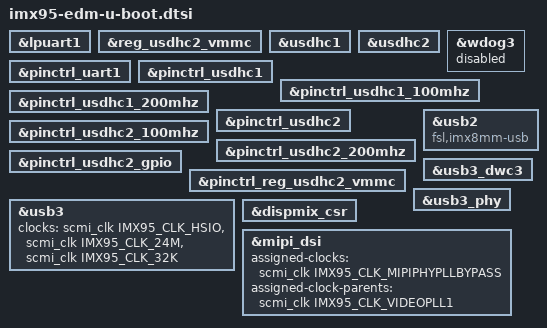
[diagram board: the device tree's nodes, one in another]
// SPDX-License-Identifier: (GPL-2.0+ OR MIT)
/*
 * Copyright 2025 Technexion Ltd.
 *
 * Author: Richard Hu <richard.hu@technexion.com>
 *
 */

#include "imx95-u-boot.dtsi"

&lpuart1 {
	bootph-pre-ram;
};

&reg_usdhc2_vmmc {
	bootph-pre-ram;
};

&usdhc1 {
	bootph-pre-ram;
};

&usdhc2 {
	bootph-pre-ram;
};

&wdog3 {
	status = "disabled";
};

&pinctrl_uart1 {
	bootph-pre-ram;
};

&pinctrl_usdhc1 {
	bootph-pre-ram;
};

&pinctrl_usdhc1_100mhz {
	bootph-pre-ram;
};

&pinctrl_usdhc1_200mhz {
	bootph-pre-ram;
};

&pinctrl_usdhc2 {
	bootph-pre-ram;
};

&pinctrl_usdhc2_100mhz {
	bootph-pre-ram;
};

&pinctrl_usdhc2_200mhz {
	bootph-pre-ram;
};

&pinctrl_usdhc2_gpio {
	bootph-pre-ram;
};

&pinctrl_reg_usdhc2_vmmc {
	bootph-pre-ram;
};

&usb2 {
	compatible = "fsl,imx8mm-usb", "fsl,imx7d-usb";
	/delete-property/power-domains;
};

&usb3 {
	clocks = <&scmi_clk IMX95_CLK_HSIO>,
		 <&scmi_clk IMX95_CLK_24M>,
		 <&scmi_clk IMX95_CLK_32K>;
	clock-names = "hsio", "ref", "suspend";
	/delete-property/power-domains;
	bootph-pre-ram;
};

&usb3_dwc3 {
	bootph-pre-ram;
};

&usb3_phy {
	bootph-pre-ram;
};

&dispmix_csr {
	/delete-property/ assigned-clocks;
	/delete-property/ assigned-clock-rates;
	/delete-property/ assigned-clock-parents;
};

&mipi_dsi {
	assigned-clocks = <&scmi_clk IMX95_CLK_MIPIPHYPLLBYPASS>;
	assigned-clock-parents = <&scmi_clk IMX95_CLK_VIDEOPLL1>;
};
